AUTOSAR XML (schema 4.0)
package /Powertrain_Components
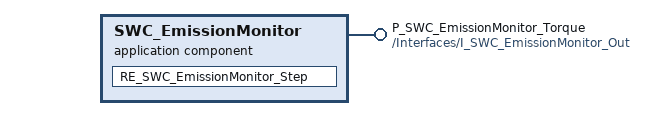
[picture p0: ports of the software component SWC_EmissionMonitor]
  application sw component type SWC_EmissionMonitor  # AUTOSAR Application SWC SWC_EmissionMonitor for Powertrain Control
    provide port P_SWC_EmissionMonitor_Torque: provided-interface=/Interfaces/I_SWC_EmissionMonitor_Out
    behavior SWC_EmissionMonitor_Behavior
      runnable RE_SWC_EmissionMonitor_Step: symbol=SWC_EmissionMonitor_Step
  sender receiver interface I_SWC_EmissionMonitor_Out
    data DE_SWC_EmissionMonitor_TorqueDemand: type=/AUTOSAR/Platform/uint32
